# RP2350 register map
Vendor: Raspberry Pi; File version: 0.1
CPU: CM33 r1p0, little endian, MPU, FPU, VTOR, 4 interrupt priority bits, 54 interrupts, 8 SAU regions
Registers are 32-bit, read-write, reset 0x0 unless marked. A register's access mark holds for its fields unless they carry their own. Offsets are from the block's base; [hi:lo] are bit positions.

## I2C0 (part 2 of 2) — DW_apb_i2c address block . List of configuration constants for the Synopsys I2C hardware (you may see references to these in I2C register header; these are *fixed* values, set at hardware design time): . IC_ULTRA_FAST_MODE ................ 0x0. IC_UFM_TBUF_CNT_DEFAULT ........... 0x8. IC_UFM_SCL_LOW_COUNT .............. 0x0008. IC_UFM_SCL_HIGH_COUNT ............. 0x0006. IC_TX_TL .......................... 0x0. IC_TX_CMD_BLOCK ................... 0x1. IC_HAS_DMA ........................ 0x1. IC_HAS_ASYNC_FIFO ................. 0x0. IC_SMBUS_ARP ...................... 0x0. IC_FIRST_DATA_BYTE_STATUS ......... 0x1. IC_INTR_IO ........................ 0x1. IC_MASTER_MODE .................... 0x1. IC_DEFAULT_ACK_GENERAL_CALL ....... 0x1. IC_INTR_POL ....................... 0x1. IC_OPTIONAL_SAR ................... 0x0. IC_DEFAULT_TAR_SLAVE_ADDR ......... 0x055. IC_DEFAULT_SLAVE_ADDR ............. 0x055. IC_DEFAULT_HS_SPKLEN .............. 0x1. IC_FS_SCL_HIGH_COUNT .............. 0x0006. IC_HS_SCL_LOW_COUNT ............... 0x0008. IC_DEVICE_ID_VALUE ................ 0x0. IC_10BITADDR_MASTER ............... 0x0. IC_CLK_FREQ_OPTIMIZATION .......... 0x0. IC_DEFAULT_FS_SPKLEN .............. 0x7. IC_ADD_ENCODED_PARAMS ............. 0x0. IC_DEFAULT_SDA_HOLD ............... 0x000001. IC_DEFAULT_SDA_SETUP .............. 0x64. IC_AVOID_RX_FIFO_FLUSH_ON_TX_ABRT . 0x0. IC_CLOCK_PERIOD ................... 100. IC_EMPTYFIFO_HOLD_MASTER_EN ....... 1. IC_RESTART_EN ..................... 0x1. IC_TX_CMD_BLOCK_DEFAULT ........... 0x0. IC_BUS_CLEAR_FEATURE .............. 0x0. IC_CAP_LOADING .................... 100. IC_FS_SCL_LOW_COUNT ............... 0x000d. APB_DATA_WIDTH .................... 32. IC_SDA_STUCK_TIMEOUT_DEFAULT ...... 0xffffffff. IC_SLV_DATA_NACK_ONLY ............. 0x1. IC_10BITADDR_SLAVE ................ 0x0. IC_CLK_TYPE ....................... 0x0. IC_SMBUS_UDID_MSB ................. 0x0. IC_SMBUS_SUSPEND_ALERT ............ 0x0. IC_HS_SCL_HIGH_COUNT .............. 0x0006. IC_SLV_RESTART_DET_EN ............. 0x1. IC_SMBUS .......................... 0x0. IC_OPTIONAL_SAR_DEFAULT ........... 0x0. IC_PERSISTANT_SLV_ADDR_DEFAULT .... 0x0. IC_USE_COUNTS ..................... 0x0. IC_RX_BUFFER_DEPTH ................ 16. IC_SCL_STUCK_TIMEOUT_DEFAULT ...... 0xffffffff. IC_RX_FULL_HLD_BUS_EN ............. 0x1. IC_SLAVE_DISABLE .................. 0x1. IC_RX_TL .......................... 0x0. IC_DEVICE_ID ...................... 0x0. IC_HC_COUNT_VALUES ................ 0x0. I2C_DYNAMIC_TAR_UPDATE ............ 0. IC_SMBUS_CLK_LOW_MEXT_DEFAULT ..... 0xffffffff. IC_SMBUS_CLK_LOW_SEXT_DEFAULT ..... 0xffffffff. IC_HS_MASTER_CODE ................. 0x1. IC_SMBUS_RST_IDLE_CNT_DEFAULT ..... 0xffff. IC_SMBUS_UDID_LSB_DEFAULT ......... 0xffffffff. IC_SS_SCL_HIGH_COUNT .............. 0x0028. IC_SS_SCL_LOW_COUNT ............... 0x002f. IC_MAX_SPEED_MODE ................. 0x2. IC_STAT_FOR_CLK_STRETCH ........... 0x0. IC_STOP_DET_IF_MASTER_ACTIVE ...... 0x0. IC_DEFAULT_UFM_SPKLEN ............. 0x1. IC_TX_BUFFER_DEPTH ................ 16
Base 0x40090000
Same registers: I2C1 0x40098000
0x38 IC_RX_TL — I2C Receive FIFO Threshold Register
  [7:0] RX_TL — Receive FIFO Threshold Level. . Controls the level of entries (or above) that triggers the RX_FULL interrupt (bit 2 in IC_RAW_INTR_STAT register). The valid range is 0-255, with the additional restriction that hardware does not allow this value to be set to a value larger than the depth of the buffer. If an attempt is made to do that, the actual value set will be the maximum depth of the buffer. A value of 0 sets the threshold for 1 entry, and a value of 255 sets the threshold for 256 entries.
0x3C IC_TX_TL — I2C Transmit FIFO Threshold Register
  [7:0] TX_TL — Transmit FIFO Threshold Level. . Controls the level of entries (or below) that trigger the TX_EMPTY interrupt (bit 4 in IC_RAW_INTR_STAT register). The valid range is 0-255, with the additional restriction that it may not be set to value larger than the depth of the buffer. If an attempt is made to do that, the actual value set will be the maximum depth of the buffer. A value of 0 sets the threshold for 0 entries, and a value of 255 sets the threshold for 255 entries.
0x40 IC_CLR_INTR ro — Clear Combined and Individual Interrupt Register
  [0] CLR_INTR — Read this register to clear the combined interrupt, all individual interrupts, and the IC_TX_ABRT_SOURCE register. This bit does not clear hardware clearable interrupts but software clearable interrupts. Refer to Bit 9 of the IC_TX_ABRT_SOURCE register for an exception to clearing IC_TX_ABRT_SOURCE. . Reset value: 0x0
0x44 IC_CLR_RX_UNDER ro — Clear RX_UNDER Interrupt Register
  [0] CLR_RX_UNDER — Read this register to clear the RX_UNDER interrupt (bit 0) of the IC_RAW_INTR_STAT register. . Reset value: 0x0
0x48 IC_CLR_RX_OVER ro — Clear RX_OVER Interrupt Register
  [0] CLR_RX_OVER — Read this register to clear the RX_OVER interrupt (bit 1) of the IC_RAW_INTR_STAT register. . Reset value: 0x0
0x4C IC_CLR_TX_OVER ro — Clear TX_OVER Interrupt Register
  [0] CLR_TX_OVER — Read this register to clear the TX_OVER interrupt (bit 3) of the IC_RAW_INTR_STAT register. . Reset value: 0x0
0x50 IC_CLR_RD_REQ ro — Clear RD_REQ Interrupt Register
  [0] CLR_RD_REQ — Read this register to clear the RD_REQ interrupt (bit 5) of the IC_RAW_INTR_STAT register. . Reset value: 0x0
0x54 IC_CLR_TX_ABRT ro — Clear TX_ABRT Interrupt Register
  [0] CLR_TX_ABRT — Read this register to clear the TX_ABRT interrupt (bit 6) of the IC_RAW_INTR_STAT register, and the IC_TX_ABRT_SOURCE register. This also releases the TX FIFO from the flushed/reset state, allowing more writes to the TX FIFO. Refer to Bit 9 of the IC_TX_ABRT_SOURCE register for an exception to clearing IC_TX_ABRT_SOURCE. . Reset value: 0x0
0x58 IC_CLR_RX_DONE ro — Clear RX_DONE Interrupt Register
  [0] CLR_RX_DONE — Read this register to clear the RX_DONE interrupt (bit 7) of the IC_RAW_INTR_STAT register. . Reset value: 0x0
0x5C IC_CLR_ACTIVITY ro — Clear ACTIVITY Interrupt Register
  [0] CLR_ACTIVITY — Reading this register clears the ACTIVITY interrupt if the I2C is not active anymore. If the I2C module is still active on the bus, the ACTIVITY interrupt bit continues to be set. It is automatically cleared by hardware if the module is disabled and if there is no further activity on the bus. The value read from this register to get status of the ACTIVITY interrupt (bit 8) of the IC_RAW_INTR_STAT register. . Reset value: 0x0
0x60 IC_CLR_STOP_DET ro — Clear STOP_DET Interrupt Register
  [0] CLR_STOP_DET — Read this register to clear the STOP_DET interrupt (bit 9) of the IC_RAW_INTR_STAT register. . Reset value: 0x0
0x64 IC_CLR_START_DET ro — Clear START_DET Interrupt Register
  [0] CLR_START_DET — Read this register to clear the START_DET interrupt (bit 10) of the IC_RAW_INTR_STAT register. . Reset value: 0x0
0x68 IC_CLR_GEN_CALL ro — Clear GEN_CALL Interrupt Register
  [0] CLR_GEN_CALL — Read this register to clear the GEN_CALL interrupt (bit 11) of IC_RAW_INTR_STAT register. . Reset value: 0x0
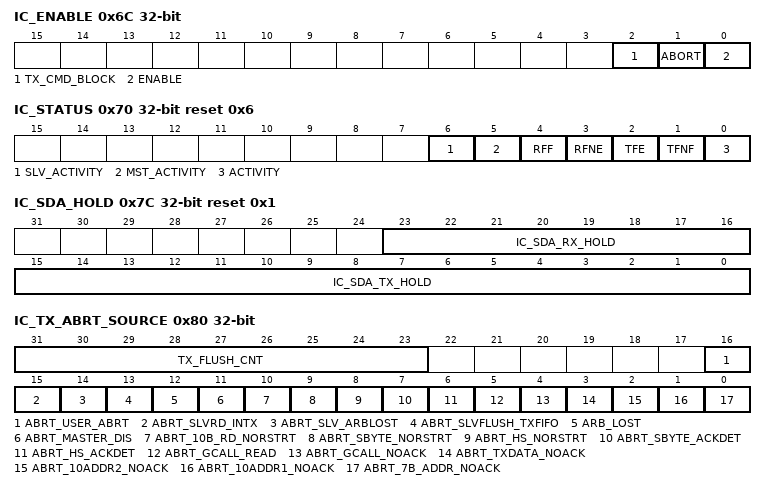
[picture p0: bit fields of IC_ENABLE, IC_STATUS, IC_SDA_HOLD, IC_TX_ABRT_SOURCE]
0x6C IC_ENABLE — I2C Enable Register
  [2] TX_CMD_BLOCK — In Master mode: - 1'b1: Blocks the transmission of data on I2C bus even if Tx FIFO has data to transmit. - 1'b0: The transmission of data starts on I2C bus automatically, as soon as the first data is available in the Tx FIFO. Note: To block the execution of Master commands, set the TX_CMD_BLOCK bit only when Tx FIFO is empty (IC_STATUS[2]==1) and Master is in Idle state (IC_STATUS[5] == 0). Any further commands put in the Tx FIFO are not executed until TX_CMD_BLOCK bit is unset. Reset value: IC_TX_CMD_BLOCK_DEFAULT
    0=NOT_BLOCKED (Tx Command execution not blocked); 1=BLOCKED (Tx Command execution blocked)
  [1] ABORT — When set, the controller initiates the transfer abort. - 0: ABORT not initiated or ABORT done - 1: ABORT operation in progress The software can abort the I2C transfer in master mode by setting this bit. The software can set this bit only when ENABLE is already set; otherwise, the controller ignores any write to ABORT bit. The software cannot clear the ABORT bit once set. In response to an ABORT, the controller issues a STOP and flushes the Tx FIFO after completing the current transfer, then sets the TX_ABORT interrupt after the abort operation. The ABORT bit is cleared automatically after the abort operation. . For a detailed description on how to abort I2C transfers, refer to 'Aborting I2C Transfers'. . Reset value: 0x0
    0=DISABLE (ABORT operation not in progress); 1=ENABLED (ABORT operation in progress)
  [0] ENABLE — Controls whether the DW_apb_i2c is enabled. - 0: Disables DW_apb_i2c (TX and RX FIFOs are held in an erased state) - 1: Enables DW_apb_i2c Software can disable DW_apb_i2c while it is active. However, it is important that care be taken to ensure that DW_apb_i2c is disabled properly. A recommended procedure is described in 'Disabling DW_apb_i2c'. . When DW_apb_i2c is disabled, the following occurs: - The TX FIFO and RX FIFO get flushed. - Status bits in the IC_INTR_STAT register are still active until DW_apb_i2c goes into IDLE state. If the module is transmitting, it stops as well as deletes the contents of the transmit buffer after the current transfer is complete. If the module is receiving, the DW_apb_i2c stops the current transfer at the end of the current byte and does not acknowledge the transfer. . In systems with asynchronous pclk and ic_clk when IC_CLK_TYPE parameter set to asynchronous (1), there is a two ic_clk delay when enabling or disabling the DW_apb_i2c. For a detailed description on how to disable DW_apb_i2c, refer to 'Disabling DW_apb_i2c' . Reset value: 0x0
    0=DISABLED (I2C is disabled); 1=ENABLED (I2C is enabled)
0x70 IC_STATUS ro reset 0x6 — I2C Status Register . This is a read-only register used to indicate the current transfer status and FIFO status. The status register may be read at any time. None of the bits in this register request an interrupt. . When the I2C is disabled by writing 0 in bit 0 of the IC_ENABLE register: - Bits 1 and 2 are set to 1 - Bits 3 and 10 are set to 0 When the master or slave state machines goes to idle and ic_en=0: - Bits 5 and 6 are set to 0
  [6] SLV_ACTIVITY — Slave FSM Activity Status. When the Slave Finite State Machine (FSM) is not in the IDLE state, this bit is set. - 0: Slave FSM is in IDLE state so the Slave part of DW_apb_i2c is not Active - 1: Slave FSM is not in IDLE state so the Slave part of DW_apb_i2c is Active Reset value: 0x0
    0=IDLE (Slave is idle); 1=ACTIVE (Slave not idle)
  [5] MST_ACTIVITY — Master FSM Activity Status. When the Master Finite State Machine (FSM) is not in the IDLE state, this bit is set. - 0: Master FSM is in IDLE state so the Master part of DW_apb_i2c is not Active - 1: Master FSM is not in IDLE state so the Master part of DW_apb_i2c is Active Note: IC_STATUS[0]-that is, ACTIVITY bit-is the OR of SLV_ACTIVITY and MST_ACTIVITY bits. . Reset value: 0x0
    0=IDLE (Master is idle); 1=ACTIVE (Master not idle)
  [4] RFF — Receive FIFO Completely Full. When the receive FIFO is completely full, this bit is set. When the receive FIFO contains one or more empty location, this bit is cleared. - 0: Receive FIFO is not full - 1: Receive FIFO is full Reset value: 0x0
    0=NOT_FULL (Rx FIFO not full); 1=FULL (Rx FIFO is full)
  [3] RFNE — Receive FIFO Not Empty. This bit is set when the receive FIFO contains one or more entries; it is cleared when the receive FIFO is empty. - 0: Receive FIFO is empty - 1: Receive FIFO is not empty Reset value: 0x0
    0=EMPTY (Rx FIFO is empty); 1=NOT_EMPTY (Rx FIFO not empty)
  [2] TFE — Transmit FIFO Completely Empty. When the transmit FIFO is completely empty, this bit is set. When it contains one or more valid entries, this bit is cleared. This bit field does not request an interrupt. - 0: Transmit FIFO is not empty - 1: Transmit FIFO is empty Reset value: 0x1
    0=NON_EMPTY (Tx FIFO not empty); 1=EMPTY (Tx FIFO is empty)
  [1] TFNF — Transmit FIFO Not Full. Set when the transmit FIFO contains one or more empty locations, and is cleared when the FIFO is full. - 0: Transmit FIFO is full - 1: Transmit FIFO is not full Reset value: 0x1
    0=FULL (Tx FIFO is full); 1=NOT_FULL (Tx FIFO not full)
  [0] ACTIVITY — I2C Activity Status. Reset value: 0x0
    0=INACTIVE (I2C is idle); 1=ACTIVE (I2C is active)
0x74 IC_TXFLR ro — I2C Transmit FIFO Level Register This register contains the number of valid data entries in the transmit FIFO buffer. It is cleared whenever: - The I2C is disabled - There is a transmit abort - that is, TX_ABRT bit is set in the IC_RAW_INTR_STAT register - The slave bulk transmit mode is aborted The register increments whenever data is placed into the transmit FIFO and decrements when data is taken from the transmit FIFO.
  [4:0] TXFLR — Transmit FIFO Level. Contains the number of valid data entries in the transmit FIFO. . Reset value: 0x0
0x78 IC_RXFLR ro — I2C Receive FIFO Level Register This register contains the number of valid data entries in the receive FIFO buffer. It is cleared whenever: - The I2C is disabled - Whenever there is a transmit abort caused by any of the events tracked in IC_TX_ABRT_SOURCE The register increments whenever data is placed into the receive FIFO and decrements when data is taken from the receive FIFO.
  [4:0] RXFLR — Receive FIFO Level. Contains the number of valid data entries in the receive FIFO. . Reset value: 0x0
0x7C IC_SDA_HOLD reset 0x1 — I2C SDA Hold Time Length Register . The bits [15:0] of this register are used to control the hold time of SDA during transmit in both slave and master mode (after SCL goes from HIGH to LOW). . The bits [23:16] of this register are used to extend the SDA transition (if any) whenever SCL is HIGH in the receiver in either master or slave mode. . Writes to this register succeed only when IC_ENABLE[0]=0. . The values in this register are in units of ic_clk period. The value programmed in IC_SDA_TX_HOLD must be greater than the minimum hold time in each mode (one cycle in master mode, seven cycles in slave mode) for the value to be implemented. . The programmed SDA hold time during transmit (IC_SDA_TX_HOLD) cannot exceed at any time the duration of the low part of scl. Therefore the programmed value cannot be larger than N_SCL_LOW-2, where N_SCL_LOW is the duration of the low part of the scl period measured in ic_clk cycles.
  [23:16] IC_SDA_RX_HOLD — Sets the required SDA hold time in units of ic_clk period, when DW_apb_i2c acts as a receiver. . Reset value: IC_DEFAULT_SDA_HOLD[23:16].
  [15:0] IC_SDA_TX_HOLD — Sets the required SDA hold time in units of ic_clk period, when DW_apb_i2c acts as a transmitter. . Reset value: IC_DEFAULT_SDA_HOLD[15:0].
0x80 IC_TX_ABRT_SOURCE ro — I2C Transmit Abort Source Register . This register has 32 bits that indicate the source of the TX_ABRT bit. Except for Bit 9, this register is cleared whenever the IC_CLR_TX_ABRT register or the IC_CLR_INTR register is read. To clear Bit 9, the source of the ABRT_SBYTE_NORSTRT must be fixed first; RESTART must be enabled (IC_CON[5]=1), the SPECIAL bit must be cleared (IC_TAR[11]), or the GC_OR_START bit must be cleared (IC_TAR[10]). . Once the source of the ABRT_SBYTE_NORSTRT is fixed, then this bit can be cleared in the same manner as other bits in this register. If the source of the ABRT_SBYTE_NORSTRT is not fixed before attempting to clear this bit, Bit 9 clears for one cycle and is then re-asserted.
  [31:23] TX_FLUSH_CNT — This field indicates the number of Tx FIFO Data Commands which are flushed due to TX_ABRT interrupt. It is cleared whenever I2C is disabled. . Reset value: 0x0 . Role of DW_apb_i2c: Master-Transmitter or Slave-Transmitter
  [16] ABRT_USER_ABRT — This is a master-mode-only bit. Master has detected the transfer abort (IC_ENABLE[1]) . Reset value: 0x0 . Role of DW_apb_i2c: Master-Transmitter
    0=ABRT_USER_ABRT_VOID (Transfer abort detected by master- scenario not present); 1=ABRT_USER_ABRT_GENERATED (Transfer abort detected by master)
  [15] ABRT_SLVRD_INTX — 1: When the processor side responds to a slave mode request for data to be transmitted to a remote master and user writes a 1 in CMD (bit 8) of IC_DATA_CMD register. . Reset value: 0x0 . Role of DW_apb_i2c: Slave-Transmitter
    0=ABRT_SLVRD_INTX_VOID (Slave trying to transmit to remote master in read mode- scenario not present); 1=ABRT_SLVRD_INTX_GENERATED (Slave trying to transmit to remote master in read mode)
  [14] ABRT_SLV_ARBLOST — This field indicates that a Slave has lost the bus while transmitting data to a remote master. IC_TX_ABRT_SOURCE[12] is set at the same time. Note: Even though the slave never 'owns' the bus, something could go wrong on the bus. This is a fail safe check. For instance, during a data transmission at the low-to-high transition of SCL, if what is on the data bus is not what is supposed to be transmitted, then DW_apb_i2c no longer own the bus. . Reset value: 0x0 . Role of DW_apb_i2c: Slave-Transmitter
    0=ABRT_SLV_ARBLOST_VOID (Slave lost arbitration to remote master- scenario not present); 1=ABRT_SLV_ARBLOST_GENERATED (Slave lost arbitration to remote master)
  [13] ABRT_SLVFLUSH_TXFIFO — This field specifies that the Slave has received a read command and some data exists in the TX FIFO, so the slave issues a TX_ABRT interrupt to flush old data in TX FIFO. . Reset value: 0x0 . Role of DW_apb_i2c: Slave-Transmitter
    0=ABRT_SLVFLUSH_TXFIFO_VOID (Slave flushes existing data in TX-FIFO upon getting read command- scenario not present); 1=ABRT_SLVFLUSH_TXFIFO_GENERATED (Slave flushes existing data in TX-FIFO upon getting read command)
  [12] ARB_LOST — This field specifies that the Master has lost arbitration, or if IC_TX_ABRT_SOURCE[14] is also set, then the slave transmitter has lost arbitration. . Reset value: 0x0 . Role of DW_apb_i2c: Master-Transmitter or Slave-Transmitter
    0=ABRT_LOST_VOID (Master or Slave-Transmitter lost arbitration- scenario not present); 1=ABRT_LOST_GENERATED (Master or Slave-Transmitter lost arbitration)
  [11] ABRT_MASTER_DIS — This field indicates that the User tries to initiate a Master operation with the Master mode disabled. . Reset value: 0x0 . Role of DW_apb_i2c: Master-Transmitter or Master-Receiver
    0=ABRT_MASTER_DIS_VOID (User initiating master operation when MASTER disabled- scenario not present); 1=ABRT_MASTER_DIS_GENERATED (User initiating master operation when MASTER disabled)
  [10] ABRT_10B_RD_NORSTRT — This field indicates that the restart is disabled (IC_RESTART_EN bit (IC_CON[5]) =0) and the master sends a read command in 10-bit addressing mode. . Reset value: 0x0 . Role of DW_apb_i2c: Master-Receiver
    0=ABRT_10B_RD_VOID (Master not trying to read in 10Bit addressing mode when RESTART disabled); 1=ABRT_10B_RD_GENERATED (Master trying to read in 10Bit addressing mode when RESTART disabled)
  [9] ABRT_SBYTE_NORSTRT — To clear Bit 9, the source of the ABRT_SBYTE_NORSTRT must be fixed first; restart must be enabled (IC_CON[5]=1), the SPECIAL bit must be cleared (IC_TAR[11]), or the GC_OR_START bit must be cleared (IC_TAR[10]). Once the source of the ABRT_SBYTE_NORSTRT is fixed, then this bit can be cleared in the same manner as other bits in this register. If the source of the ABRT_SBYTE_NORSTRT is not fixed before attempting to clear this bit, bit 9 clears for one cycle and then gets reasserted. When this field is set to 1, the restart is disabled (IC_RESTART_EN bit (IC_CON[5]) =0) and the user is trying to send a START Byte. . Reset value: 0x0 . Role of DW_apb_i2c: Master
    0=ABRT_SBYTE_NORSTRT_VOID (User trying to send START byte when RESTART disabled- scenario not present); 1=ABRT_SBYTE_NORSTRT_GENERATED (User trying to send START byte when RESTART disabled)
  [8] ABRT_HS_NORSTRT — This field indicates that the restart is disabled (IC_RESTART_EN bit (IC_CON[5]) =0) and the user is trying to use the master to transfer data in High Speed mode. . Reset value: 0x0 . Role of DW_apb_i2c: Master-Transmitter or Master-Receiver
    0=ABRT_HS_NORSTRT_VOID (User trying to switch Master to HS mode when RESTART disabled- scenario not present); 1=ABRT_HS_NORSTRT_GENERATED (User trying to switch Master to HS mode when RESTART disabled)
  [7] ABRT_SBYTE_ACKDET — This field indicates that the Master has sent a START Byte and the START Byte was acknowledged (wrong behavior). . Reset value: 0x0 . Role of DW_apb_i2c: Master
    0=ABRT_SBYTE_ACKDET_VOID (ACK detected for START byte- scenario not present); 1=ABRT_SBYTE_ACKDET_GENERATED (ACK detected for START byte)
  [6] ABRT_HS_ACKDET — This field indicates that the Master is in High Speed mode and the High Speed Master code was acknowledged (wrong behavior). . Reset value: 0x0 . Role of DW_apb_i2c: Master
    0=ABRT_HS_ACK_VOID (HS Master code ACKed in HS Mode- scenario not present); 1=ABRT_HS_ACK_GENERATED (HS Master code ACKed in HS Mode)
  [5] ABRT_GCALL_READ — This field indicates that DW_apb_i2c in the master mode has sent a General Call but the user programmed the byte following the General Call to be a read from the bus (IC_DATA_CMD[9] is set to 1). . Reset value: 0x0 . Role of DW_apb_i2c: Master-Transmitter
    0=ABRT_GCALL_READ_VOID (GCALL is followed by read from bus-scenario not present); 1=ABRT_GCALL_READ_GENERATED (GCALL is followed by read from bus)
  [4] ABRT_GCALL_NOACK — This field indicates that DW_apb_i2c in master mode has sent a General Call and no slave on the bus acknowledged the General Call. . Reset value: 0x0 . Role of DW_apb_i2c: Master-Transmitter
    0=ABRT_GCALL_NOACK_VOID (GCALL not ACKed by any slave-scenario not present); 1=ABRT_GCALL_NOACK_GENERATED (GCALL not ACKed by any slave)
  [3] ABRT_TXDATA_NOACK — This field indicates the master-mode only bit. When the master receives an acknowledgement for the address, but when it sends data byte(s) following the address, it did not receive an acknowledge from the remote slave(s). . Reset value: 0x0 . Role of DW_apb_i2c: Master-Transmitter
    0=ABRT_TXDATA_NOACK_VOID (Transmitted data non-ACKed by addressed slave-scenario not present); 1=ABRT_TXDATA_NOACK_GENERATED (Transmitted data not ACKed by addressed slave)
  [2] ABRT_10ADDR2_NOACK — This field indicates that the Master is in 10-bit address mode and that the second address byte of the 10-bit address was not acknowledged by any slave. . Reset value: 0x0 . Role of DW_apb_i2c: Master-Transmitter or Master-Receiver
    0=INACTIVE (This abort is not generated); 1=ACTIVE (Byte 2 of 10Bit Address not ACKed by any slave)
  [1] ABRT_10ADDR1_NOACK — This field indicates that the Master is in 10-bit address mode and the first 10-bit address byte was not acknowledged by any slave. . Reset value: 0x0 . Role of DW_apb_i2c: Master-Transmitter or Master-Receiver
    0=INACTIVE (This abort is not generated); 1=ACTIVE (Byte 1 of 10Bit Address not ACKed by any slave)
  [0] ABRT_7B_ADDR_NOACK — This field indicates that the Master is in 7-bit addressing mode and the address sent was not acknowledged by any slave. . Reset value: 0x0 . Role of DW_apb_i2c: Master-Transmitter or Master-Receiver
    0=INACTIVE (This abort is not generated); 1=ACTIVE (This abort is generated because of NOACK for 7-bit address)
0x84 IC_SLV_DATA_NACK_ONLY — Generate Slave Data NACK Register . The register is used to generate a NACK for the data part of a transfer when DW_apb_i2c is acting as a slave-receiver. This register only exists when the IC_SLV_DATA_NACK_ONLY parameter is set to 1. When this parameter disabled, this register does not exist and writing to the register's address has no effect. . A write can occur on this register if both of the following conditions are met: - DW_apb_i2c is disabled (IC_ENABLE[0] = 0) - Slave part is inactive (IC_STATUS[6] = 0) Note: The IC_STATUS[6] is a register read-back location for the internal slv_activity signal; the user should poll this before writing the ic_slv_data_nack_only bit.
  [0] NACK — Generate NACK. This NACK generation only occurs when DW_apb_i2c is a slave-receiver. If this register is set to a value of 1, it can only generate a NACK after a data byte is received; hence, the data transfer is aborted and the data received is not pushed to the receive buffer. . When the register is set to a value of 0, it generates NACK/ACK, depending on normal criteria. - 1: generate NACK after data byte received - 0: generate NACK/ACK normally Reset value: 0x0
    0=DISABLED (Slave receiver generates NACK normally); 1=ENABLED (Slave receiver generates NACK upon data reception only)
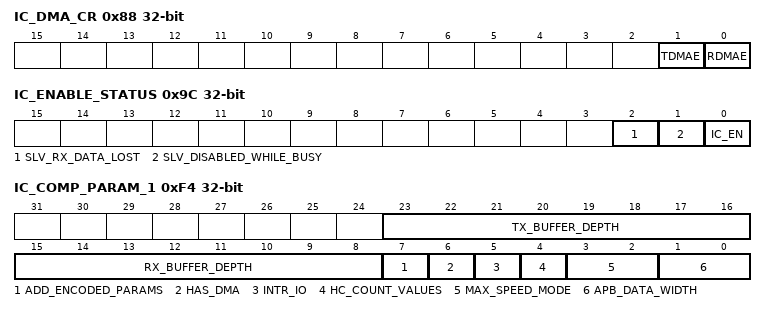
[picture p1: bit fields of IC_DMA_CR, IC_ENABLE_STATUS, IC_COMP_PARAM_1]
0x88 IC_DMA_CR — DMA Control Register . The register is used to enable the DMA Controller interface operation. There is a separate bit for transmit and receive. This can be programmed regardless of the state of IC_ENABLE.
  [1] TDMAE — Transmit DMA Enable. This bit enables/disables the transmit FIFO DMA channel. Reset value: 0x0
    0=DISABLED (transmit FIFO DMA channel disabled); 1=ENABLED (Transmit FIFO DMA channel enabled)
  [0] RDMAE — Receive DMA Enable. This bit enables/disables the receive FIFO DMA channel. Reset value: 0x0
    0=DISABLED (Receive FIFO DMA channel disabled); 1=ENABLED (Receive FIFO DMA channel enabled)
0x8C IC_DMA_TDLR — DMA Transmit Data Level Register
  [3:0] DMATDL — Transmit Data Level. This bit field controls the level at which a DMA request is made by the transmit logic. It is equal to the watermark level; that is, the dma_tx_req signal is generated when the number of valid data entries in the transmit FIFO is equal to or below this field value, and TDMAE = 1. . Reset value: 0x0
0x90 IC_DMA_RDLR — I2C Receive Data Level Register
  [3:0] DMARDL — Receive Data Level. This bit field controls the level at which a DMA request is made by the receive logic. The watermark level = DMARDL+1; that is, dma_rx_req is generated when the number of valid data entries in the receive FIFO is equal to or more than this field value + 1, and RDMAE =1. For instance, when DMARDL is 0, then dma_rx_req is asserted when 1 or more data entries are present in the receive FIFO. . Reset value: 0x0
0x94 IC_SDA_SETUP reset 0x64 — I2C SDA Setup Register . This register controls the amount of time delay (in terms of number of ic_clk clock periods) introduced in the rising edge of SCL - relative to SDA changing - when DW_apb_i2c services a read request in a slave-transmitter operation. The relevant I2C requirement is tSU:DAT (note 4) as detailed in the I2C Bus Specification. This register must be programmed with a value equal to or greater than 2. . Writes to this register succeed only when IC_ENABLE[0] = 0. . Note: The length of setup time is calculated using [(IC_SDA_SETUP - 1) * (ic_clk_period)], so if the user requires 10 ic_clk periods of setup time, they should program a value of 11. The IC_SDA_SETUP register is only used by the DW_apb_i2c when operating as a slave transmitter.
  [7:0] SDA_SETUP — SDA Setup. It is recommended that if the required delay is 1000ns, then for an ic_clk frequency of 10 MHz, IC_SDA_SETUP should be programmed to a value of 11. IC_SDA_SETUP must be programmed with a minimum value of 2.
0x98 IC_ACK_GENERAL_CALL reset 0x1 — I2C ACK General Call Register . The register controls whether DW_apb_i2c responds with a ACK or NACK when it receives an I2C General Call address. . This register is applicable only when the DW_apb_i2c is in slave mode.
  [0] ACK_GEN_CALL — ACK General Call. When set to 1, DW_apb_i2c responds with a ACK (by asserting ic_data_oe) when it receives a General Call. Otherwise, DW_apb_i2c responds with a NACK (by negating ic_data_oe).
    0=DISABLED (Generate NACK for a General Call); 1=ENABLED (Generate ACK for a General Call)
0x9C IC_ENABLE_STATUS ro — I2C Enable Status Register . The register is used to report the DW_apb_i2c hardware status when the IC_ENABLE[0] register is set from 1 to 0; that is, when DW_apb_i2c is disabled. . If IC_ENABLE[0] has been set to 1, bits 2:1 are forced to 0, and bit 0 is forced to 1. . If IC_ENABLE[0] has been set to 0, bits 2:1 is only be valid as soon as bit 0 is read as '0'. . Note: When IC_ENABLE[0] has been set to 0, a delay occurs for bit 0 to be read as 0 because disabling the DW_apb_i2c depends on I2C bus activities.
  [2] SLV_RX_DATA_LOST — Slave Received Data Lost. This bit indicates if a Slave-Receiver operation has been aborted with at least one data byte received from an I2C transfer due to the setting bit 0 of IC_ENABLE from 1 to 0. When read as 1, DW_apb_i2c is deemed to have been actively engaged in an aborted I2C transfer (with matching address) and the data phase of the I2C transfer has been entered, even though a data byte has been responded with a NACK. . Note: If the remote I2C master terminates the transfer with a STOP condition before the DW_apb_i2c has a chance to NACK a transfer, and IC_ENABLE[0] has been set to 0, then this bit is also set to 1. . When read as 0, DW_apb_i2c is deemed to have been disabled without being actively involved in the data phase of a Slave-Receiver transfer. . Note: The CPU can safely read this bit when IC_EN (bit 0) is read as 0. . Reset value: 0x0
    0=INACTIVE (Slave RX Data is not lost); 1=ACTIVE (Slave RX Data is lost)
  [1] SLV_DISABLED_WHILE_BUSY — Slave Disabled While Busy (Transmit, Receive). This bit indicates if a potential or active Slave operation has been aborted due to the setting bit 0 of the IC_ENABLE register from 1 to 0. This bit is set when the CPU writes a 0 to the IC_ENABLE register while: (a) DW_apb_i2c is receiving the address byte of the Slave-Transmitter operation from a remote master; . OR, (b) address and data bytes of the Slave-Receiver operation from a remote master. . When read as 1, DW_apb_i2c is deemed to have forced a NACK during any part of an I2C transfer, irrespective of whether the I2C address matches the slave address set in DW_apb_i2c (IC_SAR register) OR if the transfer is completed before IC_ENABLE is set to 0 but has not taken effect. . Note: If the remote I2C master terminates the transfer with a STOP condition before the DW_apb_i2c has a chance to NACK a transfer, and IC_ENABLE[0] has been set to 0, then this bit will also be set to 1. . When read as 0, DW_apb_i2c is deemed to have been disabled when there is master activity, or when the I2C bus is idle. . Note: The CPU can safely read this bit when IC_EN (bit 0) is read as 0. . Reset value: 0x0
    0=INACTIVE (Slave is disabled when it is idle); 1=ACTIVE (Slave is disabled when it is active)
  [0] IC_EN — ic_en Status. This bit always reflects the value driven on the output port ic_en. - When read as 1, DW_apb_i2c is deemed to be in an enabled state. - When read as 0, DW_apb_i2c is deemed completely inactive. Note: The CPU can safely read this bit anytime. When this bit is read as 0, the CPU can safely read SLV_RX_DATA_LOST (bit 2) and SLV_DISABLED_WHILE_BUSY (bit 1). . Reset value: 0x0
    0=DISABLED (I2C disabled); 1=ENABLED (I2C enabled)
0xA0 IC_FS_SPKLEN reset 0x7 — I2C SS, FS or FM+ spike suppression limit . This register is used to store the duration, measured in ic_clk cycles, of the longest spike that is filtered out by the spike suppression logic when the component is operating in SS, FS or FM+ modes. The relevant I2C requirement is tSP (table 4) as detailed in the I2C Bus Specification. This register must be programmed with a minimum value of 1.
  [7:0] IC_FS_SPKLEN — This register must be set before any I2C bus transaction can take place to ensure stable operation. This register sets the duration, measured in ic_clk cycles, of the longest spike in the SCL or SDA lines that will be filtered out by the spike suppression logic. This register can be written only when the I2C interface is disabled which corresponds to the IC_ENABLE[0] register being set to 0. Writes at other times have no effect. The minimum valid value is 1; hardware prevents values less than this being written, and if attempted results in 1 being set. or more information, refer to 'Spike Suppression'.
0xA8 IC_CLR_RESTART_DET ro — Clear RESTART_DET Interrupt Register
  [0] CLR_RESTART_DET — Read this register to clear the RESTART_DET interrupt (bit 12) of IC_RAW_INTR_STAT register. . Reset value: 0x0
0xF4 IC_COMP_PARAM_1 ro — Component Parameter Register 1 . Note This register is not implemented and therefore reads as 0. If it was implemented it would be a constant read-only register that contains encoded information about the component's parameter settings. Fields shown below are the settings for those parameters
  [23:16] TX_BUFFER_DEPTH — TX Buffer Depth = 16
  [15:8] RX_BUFFER_DEPTH — RX Buffer Depth = 16
  [7] ADD_ENCODED_PARAMS — Encoded parameters not visible
  [6] HAS_DMA — DMA handshaking signals are enabled
  [5] INTR_IO — COMBINED Interrupt outputs
  [4] HC_COUNT_VALUES — Programmable count values for each mode.
  [3:2] MAX_SPEED_MODE — MAX SPEED MODE = FAST MODE
  [1:0] APB_DATA_WIDTH — APB data bus width is 32 bits
0xF8 IC_COMP_VERSION ro reset 0x3230312A — I2C Component Version Register
0xFC IC_COMP_TYPE ro reset 0x44570140 — I2C Component Type Register
  [31:0] IC_COMP_TYPE — Designware Component Type number = 0x44_57_01_40. This assigned unique hex value is constant and is derived from the two ASCII letters 'DW' followed by a 16-bit unsigned number.
